# M4L1 register map
File version: 0.1
Registers are 32-bit, read-write, reset 0x0 unless marked. A register's access mark holds for its fields unless they carry their own. Offsets are from the block's base; [hi:lo] are bit positions.

## T32A0 — 16-bit Timer_Event Counter (TB)
Base 0x40061000
Same registers: T32A1 0x40061400, T32A2 0x40061800, T32A3 0x40061C00
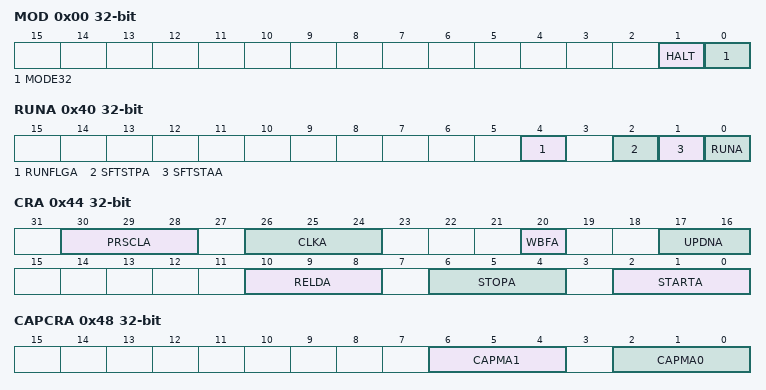
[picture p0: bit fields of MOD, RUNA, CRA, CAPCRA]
0x00 MOD — T32A Mode Register
  [1] HALT, [0] MODE32
0x40 RUNA — T32A Run Register A
  [4] RUNFLGA ro, [2] SFTSTPA wo, [1] SFTSTAA wo, [0] RUNA
0x44 CRA — T32A Counter Control Register A
  [30:28] PRSCLA, [26:24] CLKA, [20] WBFA, [17:16] UPDNA, [10:8] RELDA, [6:4] STOPA, [2:0] STARTA
0x48 CAPCRA — T32A Capture Control Register A
  [6:4] CAPMA1, [2:0] CAPMA0
0x4C OUTCRA0 wo — T32A Output Control Register A0
  [1:0] OCRA
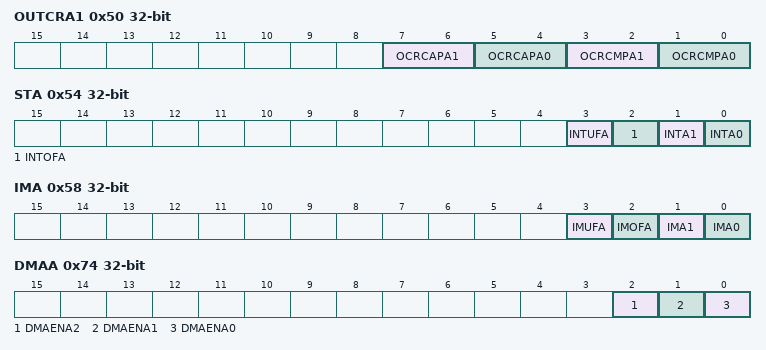
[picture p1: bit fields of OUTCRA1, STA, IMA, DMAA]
0x50 OUTCRA1 — T32A Output Control Register A1
  [7:6] OCRCAPA1, [5:4] OCRCAPA0, [3:2] OCRCMPA1, [1:0] OCRCMPA0
0x54 STA — T32A Status Register A
  [3] INTUFA, [2] INTOFA, [1] INTA1, [0] INTA0
0x58 IMA — T32A Interrupt Mask Register A
  [3] IMUFA, [2] IMOFA, [1] IMA1, [0] IMA0
0x5C TMRA ro — T32A Counter Capture Register A
  [15:0] TMRA
0x60 RELDA — T32A Counter Reload Register A
  [15:0] RELDA
0x64 RGA0 — T32A Timer Register A0
  [15:0] RGA0
0x68 RGA1 — T32A Timer Register A1
  [15:0] RGA1
0x6C CAPA0 ro — T32A Timer Capture A0 Register
  [15:0] CAPA0
0x70 CAPA1 ro — T32A Timer Cupture A1 Register
  [15:0] CAPA1
0x74 DMAA — T32A DMA Request Enable Register A
  [2] DMAENA2, [1] DMAENA1, [0] DMAENA0
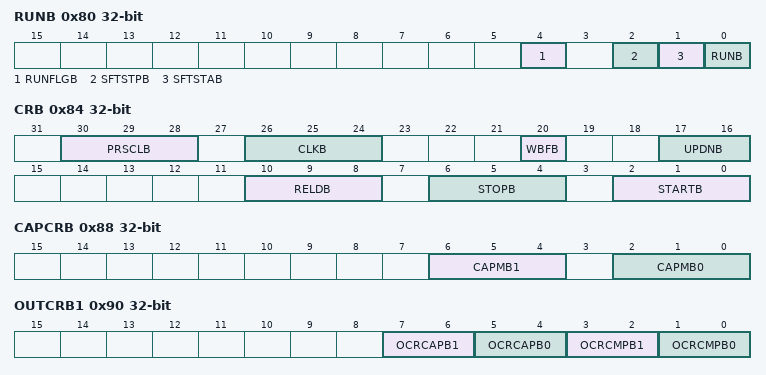
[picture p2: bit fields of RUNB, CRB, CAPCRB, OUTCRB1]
0x80 RUNB — T32A Run Register B
  [4] RUNFLGB ro, [2] SFTSTPB wo, [1] SFTSTAB wo, [0] RUNB
0x84 CRB — T32A Counter Control Register B
  [30:28] PRSCLB, [26:24] CLKB, [20] WBFB, [17:16] UPDNB, [10:8] RELDB, [6:4] STOPB, [2:0] STARTB
0x88 CAPCRB — T32A Capture Control Register B
  [6:4] CAPMB1, [2:0] CAPMB0
0x8C OUTCRB0 wo — T32A Output Control Register B0
  [1:0] OCRB
0x90 OUTCRB1 — T32A Output Control Register B1
  [7:6] OCRCAPB1, [5:4] OCRCAPB0, [3:2] OCRCMPB1, [1:0] OCRCMPB0
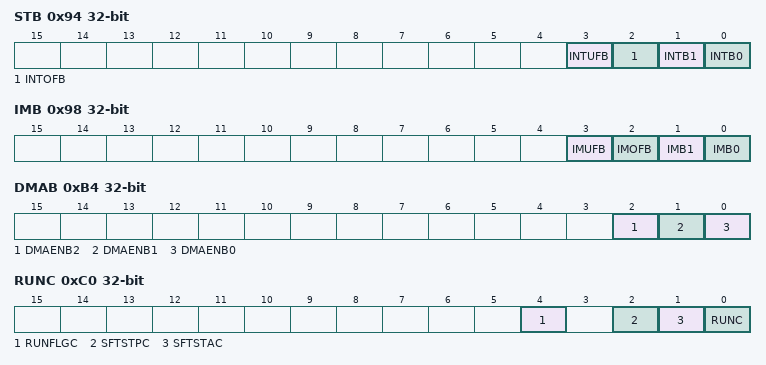
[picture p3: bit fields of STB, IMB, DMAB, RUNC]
0x94 STB — T32A Status Register B
  [3] INTUFB, [2] INTOFB, [1] INTB1, [0] INTB0
0x98 IMB — T32A Interrupt Mask Register B
  [3] IMUFB, [2] IMOFB, [1] IMB1, [0] IMB0
0x9C TMRB ro — T32A Counter Capture Register B
  [15:0] TMRB
0xA0 RELDB — T32A Counter Reload Register B
  [15:0] RELDB
0xA4 RGB0 — T32A Timer Register B0
  [15:0] RGB0
0xA8 RGB1 — T32A Timer Register B1
  [15:0] RGB1
0xAC CAPB0 ro — T32A Timer Capture B0 Register
  [15:0] CAPB0
0xB0 CAPB1 ro — T32A Timer Capture B1 Register
  [15:0] CAPB1
0xB4 DMAB — T32A DMA Request Enable Register B
  [2] DMAENB2, [1] DMAENB1, [0] DMAENB0
0xC0 RUNC — T32A Run Register C
  [4] RUNFLGC ro, [2] SFTSTPC wo, [1] SFTSTAC wo, [0] RUNC
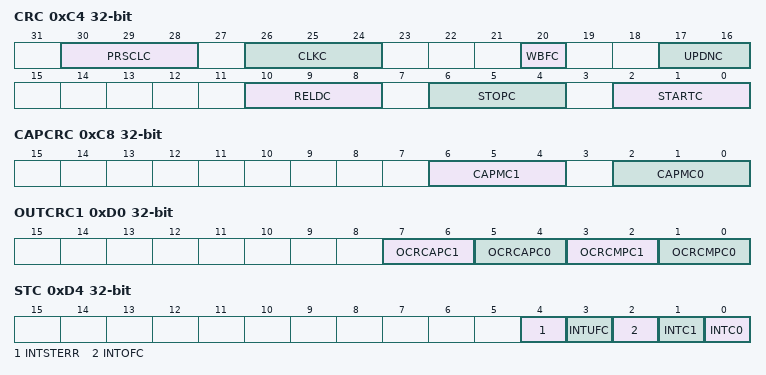
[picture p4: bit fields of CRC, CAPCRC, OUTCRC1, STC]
0xC4 CRC — T32A Counter Control Register C
  [30:28] PRSCLC, [26:24] CLKC, [20] WBFC, [17:16] UPDNC, [10:8] RELDC, [6:4] STOPC, [2:0] STARTC
0xC8 CAPCRC — T32A Capture Control Register C
  [6:4] CAPMC1, [2:0] CAPMC0
0xCC OUTCRC0 wo — T32A Output Control Register C0
  [1:0] OCRC
0xD0 OUTCRC1 — T32A Output Control Register C1
  [7:6] OCRCAPC1, [5:4] OCRCAPC0, [3:2] OCRCMPC1, [1:0] OCRCMPC0
0xD4 STC — T32A Status Register C
  [4] INTSTERR, [3] INTUFC, [2] INTOFC, [1] INTC1, [0] INTC0
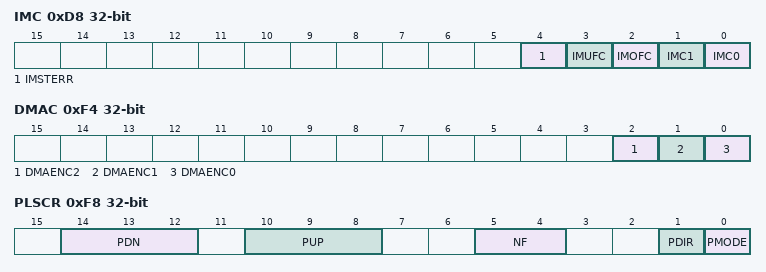
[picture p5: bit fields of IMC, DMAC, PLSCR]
0xD8 IMC — T32A Interrupt Mask Register C
  [4] IMSTERR, [3] IMUFC, [2] IMOFC, [1] IMC1, [0] IMC0
0xDC TMRC ro — T32A Counter Capture Register C
0xE0 RELDC — T32A Counter Reload Register C
0xE4 RGC0 — T32A Timer Register C0
0xE8 RGC1 — T32A Timer Register C1
0xEC CAPC0 ro — T32A Timer Capture C0 Register
0xF0 CAPC1 ro — T32A Capture Register C1
0xF4 DMAC — T32A DMA Request Enable Register C
  [2] DMAENC2, [1] DMAENC1, [0] DMAENC0
0xF8 PLSCR — T32A Pulse Count Control Register
  [14:12] PDN, [10:8] PUP, [5:4] NF, [1] PDIR, [0] PMODE

## GP — General Purpose Register
Base 0x4003FF00
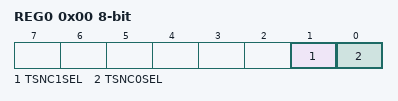
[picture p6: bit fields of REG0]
0x00 REG0 8-bit — General Purpose Register 0
  [1] TSNC1SEL, [0] TSNC0SEL

## UART0 — UART
Base 0x4006E000
Same registers: UART1 0x4006E400, UART2 0x4006E800
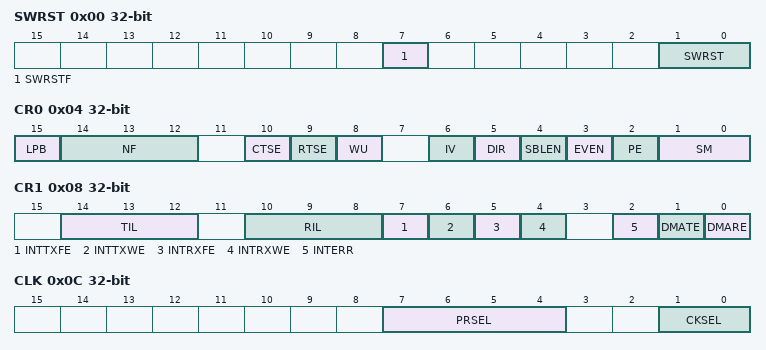
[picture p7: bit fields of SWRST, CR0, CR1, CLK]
0x00 SWRST — UART Software Reset Register
  [7] SWRSTF ro, [1:0] SWRST wo
0x04 CR0 — UART Control Register 0
  [15] LPB, [14:12] NF, [10] CTSE, [9] RTSE, [8] WU, [6] IV, [5] DIR, [4] SBLEN, [3] EVEN, [2] PE, [1:0] SM
0x08 CR1 — UART Control Register 1
  [14:12] TIL, [10:8] RIL, [7] INTTXFE, [6] INTTXWE, [5] INTRXFE, [4] INTRXWE, [2] INTERR, [1] DMATE, [0] DMARE
0x0C CLK — UART Clock Control Register
  [7:4] PRSEL, [1:0] CKSEL
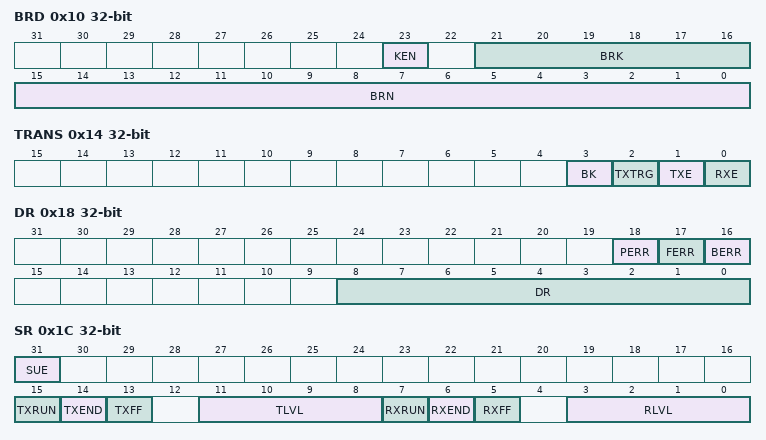
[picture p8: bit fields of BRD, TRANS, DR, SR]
0x10 BRD — UART Baud Rate Register
  [23] KEN, [21:16] BRK, [15:0] BRN
0x14 TRANS — UART Transfer Enable Register
  [3] BK, [2] TXTRG, [1] TXE, [0] RXE
0x18 DR (reset mask 0xFFFFFE00) — UART Data Register
  [18] PERR ro, [17] FERR ro, [16] BERR ro, [8:0] DR
0x1C SR (reset mask 0xFFFFFF) — UART Status Register
  [31] SUE ro, [15] TXRUN ro, [14] TXEND, [13] TXFF, [11:8] TLVL ro, [7] RXRUN ro, [6] RXEND, [5] RXFF, [3:0] RLVL ro
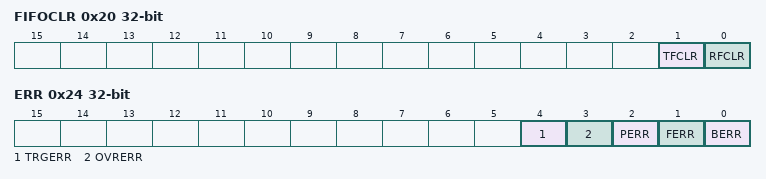
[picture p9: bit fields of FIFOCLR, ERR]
0x20 FIFOCLR wo — UART FIFO Clear Register
  [1] TFCLR, [0] RFCLR
0x24 ERR — UART Error Register
  [4] TRGERR, [3] OVRERR, [2] PERR, [1] FERR, [0] BERR
